# MIMXRT685S_cm33 register map
Vendor: nxp.com; File version: 1.0
CPU: CM33 r2p0, little endian, MPU, FPU, VTOR, 3 interrupt priority bits
Registers are 32-bit, read-write, reset 0x0 unless marked. A register's access mark holds for its fields unless they carry their own. Offsets are from the block's base; [hi:lo] are bit positions; {n}, {i} and the like mark numbered series.

## OCOTP — LPC-Next0 OTP controller
Base 0x40130000
{0x0+4i} OTP_SHADOW[{i}] (i=0..495) reset not defined — OTP shadow register N
  [31:0] shadow — OTP shadow register
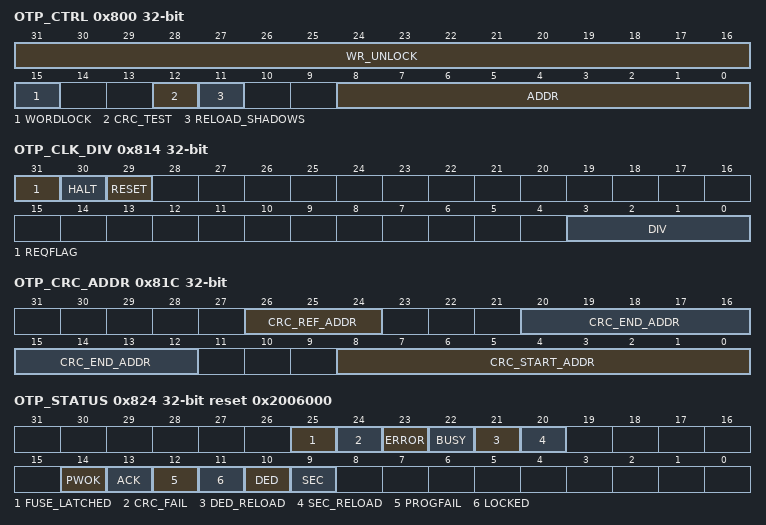
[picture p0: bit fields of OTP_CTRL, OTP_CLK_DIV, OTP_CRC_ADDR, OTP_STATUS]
0x800 OTP_CTRL — Control/address register
  [31:16] WR_UNLOCK — Write 0x3E77 to enable OTP write accesses. NOTE: The write operation must be unlocked for each word by writing 0x3E77 to WR_UNLOCK field. Then writing to OTP_WRITE_DATA register will automatically start the programming procedure.
  [15] WORDLOCK — Set to write-lock the fuse word when it's being programming. When programming with ECC mode, it recommends to set this bit.
  [12] CRC_TEST — Set to start CRC calculation. This operation will automatically set OTP_STATUS.BUSY. Once CRC is calculation done, OTP_STATUS.BUSY and CRC_TEST are automatically cleared by the controller
  [11] RELOAD_SHADOWS — Set to force re-loading the shadow registers (HW/SW capability and LOCK). This operation will automatically set OTP_STATUS.BUSY. Once the shadow registers have been re-loaded, OTP_STATUS.BUSY and RELOAD_SHADOWS are automatically cleared by the controller
  [8:0] ADDR — OTP word address for read/programming
0x804 OTP_PDN reset 0x1 — Power-down register
  [0] PDN — This bit indicates the PDN value of OTP memory. Writing 1 to the bit to clear PDN. Writing 0 has no effect. Note: Software need to write 1 to this bit to shut off power of OTP memory after system power up. At the beginning of every fuse operation, the controller will automatically turn-on power to the OPT memory. After every fuse operation, software also need to write 1 to this bit to shut off power to the OTP memory to reduce power consumption.
0x808 OTP_WRITE_DATA ro reset not defined — OTP programming data register
  [31:0] WRITE_DATA — Fuse word programming data. After the write operation is unlocked in OTP_CTRL register, writing data to this register automatically start the programming procedure.
0x80C OTP_READ_CTRL — OTP read start register
  [0] READ
0x810 OTP_READ_DATA ro
  [31:0] READ_DATA — Fuse word read data from read operation
0x814 OTP_CLK_DIV — OTP clock divider register
  [31] REQFLAG ro — Divider status flag. Set when a change is made to the divider value, cleared when the change is complete.
  [30] HALT — Halts the divider counter. The intent is to allow the divider's clock source to be changed without the risk of a glitch at the output.
  [29] RESET — Resets the divider counter. Can be used to make sure a new divider value is used right away rather than completing the previous count.
  [3:0] DIV — Clock divider value by -1 encoding. It's used to generate the clock to OTP memory (otp_clk) with apb_clk. The maximum otp_clk frequency is 120Mhz. 0: Divide by 1
    {v}=Divide by {v+1} (v=0..15)
0x81C OTP_CRC_ADDR — CRC address range register
  [26:24] CRC_REF_ADDR — Specify which of the 8 CRC reference value to use for CRC calculation. When the CRC result for the fuse data from CRC_START_ADDR to CRC_AND_ADDR and this CRC reference value is 0, the CRC check passes.
  [20:12] CRC_END_ADDR — CRC ending fuse word address
  [8:0] CRC_START_ADDR — CRC starting fuse word address
0x820 OTP_CRC_VALUE — CRC result register
  [31:0] CRC_VALUE — The CRC result value. When it is locked, reading from it returns value 32hBADA_BADA
0x824 OTP_STATUS reset 0x2006000 — Status register
  [25] FUSE_LATCHED ro — Indicate all shadows registers have been loaded with their corresponding fuse words when set by the controller after reset.
  [24] CRC_FAIL — CRC failed when set by hardware for CRC operation. Write 1 to clear.
  [23] ERROR — Set by the controller when a read/write access to a locked region (OTP or shadow register) is requested. Writing 1 to clear it before any further access can be performed. This bit can only be set by the controller.
  [22] BUSY ro — OTP controller status bit. When active, no new write or read access to OTP (including RELOAD_SHADOWS) can be performed. Cleared by the controller when the access completes. After reset (or after setting RELOAD_SHADOWS), this bit is set by the controller and cleared after all the shadow registers are successfully loaded.
  [21] DED_RELOAD — OTP Double Error Detect status of ECC during reload process. Write 1 to clear.
  [20] SEC_RELOAD — OTP Single Error Corrected status of ECC during reload process. Write 1 to clear.
  [14] PWOK ro — OTP Power OK status. Indicate that power VDD are in the operating range.
  [13] ACK ro — OTP ACK value
  [12] PROGFAIL — OTP PROGFAIL status. Write 1 to clear.
  [11] LOCKED — OTP LOCKED status during read/write operation. Write 1 to clear.
  [10] DED — OTP Double Error Detection status of ECC during read operation. Write 1 to clear.
  [9] SEC — OTP Single Error Corrected status of ECC during read operation. Write 1 to clear.
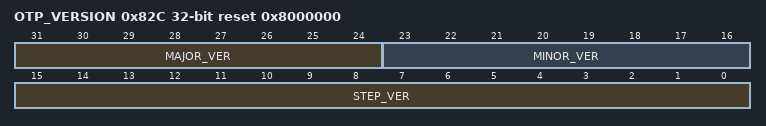
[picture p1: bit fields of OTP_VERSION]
0x82C OTP_VERSION ro reset 0x8000000 — VERSION ID register
  [31:24] MAJOR_VER — OTP controller major version
  [23:16] MINOR_VER — OTP controller minor version
  [15:0] STEP_VER — OTP controller step version
